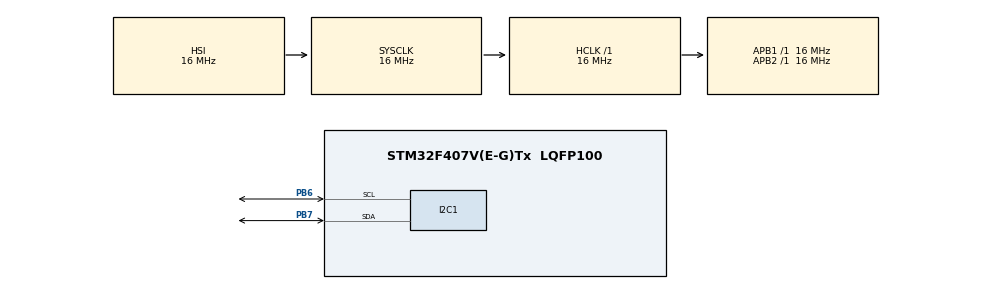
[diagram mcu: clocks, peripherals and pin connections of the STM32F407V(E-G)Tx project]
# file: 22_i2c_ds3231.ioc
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I2C1.I2C_Mode=I2C_Fast
Mcu.Family=STM32F4
Mcu.Name=STM32F407V(E-G)Tx
Mcu.Package=LQFP100
NVIC.PriorityGroup=NVIC_PRIORITYGROUP_4
PB6.Mode=I2C
PB6.Signal=I2C1_SCL
PB7.Mode=I2C
PB7.Signal=I2C1_SDA
ProjectManager.HeapSize=0x200
ProjectManager.StackSize=0x400
ProjectManager.TargetToolchain=STM32CubeIDE
RCC.AHBFreq_Value=16000000
RCC.APB1Freq_Value=16000000
RCC.APB2Freq_Value=16000000
RCC.CortexFreq_Value=16000000
RCC.HSE_VALUE=25000000
RCC.HSI_VALUE=16000000
RCC.LSE_VALUE=32768
RCC.SYSCLKFreq_VALUE=16000000
RCC.VCOOutputFreq_Value=192000000
board=custom

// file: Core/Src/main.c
/* USER CODE BEGIN Header */
/**
 ******************************************************************************
 * @file           : main.c
 * @brief          : Main program body
 ******************************************************************************
 * @attention
 *
 * Copyright (c) 2026 STMicroelectronics.
 * All rights reserved.
 *
 * This software is licensed under terms that can be found in the LICENSE file
 * in the root directory of this software component.
 * If no LICENSE file comes with this software, it is provided AS-IS.
 *
 ******************************************************************************
 */
/* USER CODE END Header */
#include "main.h"

/* USER CODE BEGIN PD */
#define DS3231_WRITE_ADDRESS      0xD0      //208 write adresi  D0 a eşit hexte
#define DS3231_READ_ADDRESS       0xD1      //209 read adresi  D1 a eşit hexte

/* USER CODE END PD */

I2C_HandleTypeDef hi2c1;

/* USER CODE BEGIN PV */
uint8_t adress;
typedef struct {
	uint8_t second;
	uint8_t minute;
	uint8_t hour;
	uint8_t dayofweek;
	uint8_t dayofmouth;
	uint8_t mouth;
	uint16_t year;

}ds3231_time_t;

ds3231_time_t ds3231Time;

/* USER CODE END PV */

void SystemClock_Config(void);
static void MX_GPIO_Init(void);
static void MX_I2C1_Init(void);

/* USER CODE BEGIN 0 */
uint8_t DEC_to_BCD(uint8_t value) {
	return (uint8_t) (value / 10 * 16) + (value % 10);
	//return(value/10 << 4)+(value%10)
}
uint8_t BCD_to_DEC(uint8_t value) {
	return (uint8_t) (value / 16 * 10) + (value % 16);
	//return(value>> 4 *10)+(value%10)
}

void DS3231_set_time(uint8_t second, uint8_t minute, uint8_t hour,
		uint8_t dayofweek, uint8_t dayofmouth, uint8_t mouth, uint8_t year) {

	uint8_t time_data[7] = { 0 };
	time_data[0] = DEC_to_BCD(second);
	time_data[1] = DEC_to_BCD(minute);
	time_data[2] = DEC_to_BCD(hour);
	time_data[3] = DEC_to_BCD(dayofweek);
	time_data[4] = DEC_to_BCD(dayofmouth);
	time_data[5] = DEC_to_BCD(mouth);
	time_data[6] = DEC_to_BCD(year);

	HAL_I2C_Mem_Write(&hi2c1, DS3231_WRITE_ADDRESS, 0x00, 1, time_data, 7,
			HAL_MAX_DELAY);

}
ds3231_time_t DS3231_get_time(void) {

	ds3231_time_t dsTime = { 0 };
	uint8_t receive_time[7];
	if (HAL_I2C_Mem_Read(&hi2c1, DS3231_READ_ADDRESS, 0x00, 1, receive_time, 7,HAL_MAX_DELAY)== HAL_OK) {
		dsTime.second = BCD_to_DEC(receive_time[0]);
		dsTime.minute = BCD_to_DEC(receive_time[1]);
		dsTime.hour = BCD_to_DEC(receive_time[2]);
		dsTime.dayofmouth = BCD_to_DEC(receive_time[3]);
		dsTime.dayofweek = BCD_to_DEC(receive_time[4]);
		dsTime.mouth = BCD_to_DEC(receive_time[5]);
		dsTime.year = BCD_to_DEC(receive_time[6])+ 2000 ;

	}
	return dsTime;
}
/* USER CODE END 0 */

int main(void) {

	/* MCU Configuration--------------------------------------------------------*/

	/* Reset of all peripherals, Initializes the Flash interface and the Systick. */
	HAL_Init();

	/* Configure the system clock */
	SystemClock_Config();

	/* Initialize all configured peripherals */
	MX_GPIO_Init();
	MX_I2C1_Init();
	/* USER CODE BEGIN 2 */

	// (+) Transmit in master mode an amount of data in blocking mode using HAL_I2C_Master_Transmit()
	// (+) Receive in master mode an amount of data in blocking mode using HAL_I2C_Master_Receive()
	// (+) Write an amount of data in blocking mode to a specific memory address using HAL_I2C_Mem_Write()
	// (+) Read an amount of data in blocking mode from a specific memory address using HAL_I2C_Mem_Read()
	//   (++) HAL_I2C_IsDeviceReady()
	DS3231_set_time(0, 0, 12, 3, 13, 6, 35);
	/* USER CODE END 2 */

	/* Infinite loop */
	while (1) {

		/* USER CODE BEGIN 3 */

		/*
		 for(int i=0; i<250 ; i++)
		 {
		 if(HAL_I2C_IsDeviceReady(&hi2c1, i, 1, 100) == HAL_OK)
		 {
		 adress = i;
		 }
		 }
		 */
		ds3231Time = DS3231_get_time();
		HAL_Delay(3000);

	}
	/* USER CODE END 3 */
}

void SystemClock_Config(void) {
	RCC_OscInitTypeDef RCC_OscInitStruct = { 0 };
	RCC_ClkInitTypeDef RCC_ClkInitStruct = { 0 };

	/** Configure the main internal regulator output voltage
	 */
	__HAL_RCC_PWR_CLK_ENABLE();
	__HAL_PWR_VOLTAGESCALING_CONFIG(PWR_REGULATOR_VOLTAGE_SCALE1);

	/** Initializes the RCC Oscillators according to the specified parameters
	 * in the RCC_OscInitTypeDef structure.
	 */
	RCC_OscInitStruct.OscillatorType = RCC_OSCILLATORTYPE_HSI;
	RCC_OscInitStruct.HSIState = RCC_HSI_ON;
	RCC_OscInitStruct.HSICalibrationValue = RCC_HSICALIBRATION_DEFAULT;
	RCC_OscInitStruct.PLL.PLLState = RCC_PLL_NONE;
	if (HAL_RCC_OscConfig(&RCC_OscInitStruct) != HAL_OK) {
		Error_Handler();
	}

	/** Initializes the CPU, AHB and APB buses clocks
	 */
	RCC_ClkInitStruct.ClockType = RCC_CLOCKTYPE_HCLK | RCC_CLOCKTYPE_SYSCLK
			| RCC_CLOCKTYPE_PCLK1 | RCC_CLOCKTYPE_PCLK2;
	RCC_ClkInitStruct.SYSCLKSource = RCC_SYSCLKSOURCE_HSI;
	RCC_ClkInitStruct.AHBCLKDivider = RCC_SYSCLK_DIV1;
	RCC_ClkInitStruct.APB1CLKDivider = RCC_HCLK_DIV1;
	RCC_ClkInitStruct.APB2CLKDivider = RCC_HCLK_DIV1;

	if (HAL_RCC_ClockConfig(&RCC_ClkInitStruct, FLASH_LATENCY_0) != HAL_OK) {
		Error_Handler();
	}
}

static void MX_I2C1_Init(void) {

	hi2c1.Instance = I2C1;
	hi2c1.Init.ClockSpeed = 400000;
	hi2c1.Init.DutyCycle = I2C_DUTYCYCLE_2;
	hi2c1.Init.OwnAddress1 = 0;
	hi2c1.Init.AddressingMode = I2C_ADDRESSINGMODE_7BIT;
	hi2c1.Init.DualAddressMode = I2C_DUALADDRESS_DISABLE;
	hi2c1.Init.OwnAddress2 = 0;
	hi2c1.Init.GeneralCallMode = I2C_GENERALCALL_DISABLE;
	hi2c1.Init.NoStretchMode = I2C_NOSTRETCH_DISABLE;
	if (HAL_I2C_Init(&hi2c1) != HAL_OK) {
		Error_Handler();
	}

}

static void MX_GPIO_Init(void) {

	/* GPIO Ports Clock Enable */
	__HAL_RCC_GPIOB_CLK_ENABLE();

}

void Error_Handler(void) {
	__disable_irq();
	while (1) {
	}
}
